# RTS591x register map
Vendor: Realtek Semiconductor Corp.; Series: RTS591x Series; File version: 1.0
CPU: ARMV8MML r0p0, little endian, MPU, FPU, VTOR, 3 interrupt priority bits, 4 SAU regions
Registers are 32-bit, read-write, reset 0x0 unless marked. A register's access mark holds for its fields unless they carry their own. Offsets are from the block's base; [hi:lo] are bit positions; {n}, {i} and the like mark numbered series; 'fields as' and 'values as' point back to an identical list.

## SPIC — SPIC Controller
Base 0x40010200
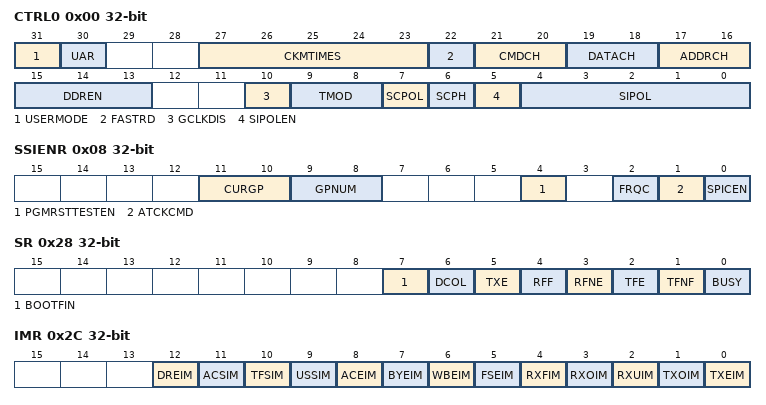
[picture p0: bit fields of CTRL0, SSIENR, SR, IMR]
0x00 CTRL0 — CONTROL #0 REGISTER0
  [31] USERMODE — User Mode Bit
    0=AUTO_MODE (User can't push data to FIFO and set SSIENR to 1); 1=USER_MODE (User can push data to FIFO and set SSIENR to 1)
  [30] UAR — User Mode Bit Auto Reset After Current User Mode Transaction is Over
    0=DISABLE (Disable UAR); 1=ENABLE (Enable UAR)
  [27:23] CKMTIMES — Check Times
  [22] FASTRD — Use Fast Read Command in User Mode
    0=DISABLE; 1=ENABLE (Use FBAUDR to generate spi_sclk)
  [21:20] CMDCH — Channel Number of Command Phase in Transmitting or Receiving Data
    0=SINGLE (Single mode); 1=Dual mode; 2=QUAD (Quad mode); 3=OCTAL (Octal mode)
  [19:18] DATACH — Channel Number of Data in Transmitting or Receiving Data
    values as CMDCH
  [17:16] ADDRCH — Channel Number of Address Phase After Command Phase
    values as CMDCH
  [15:13] DDREN — DDR Mode Enable in CMD_CH/DATA_CH/ADDR_CH
  [10] GCLKDIS — Gate Clock of ICG Cell Disable
    0=ENABLE; 1=DISABLE
  [9:8] TMOD — Transfer Mode
    0=TRANSMIT (Transmit mode); other=RECEIVE (Receive mode)
  [7] SCPOL — Serial Clock Polarity
    0=LOW (INACTIVE state of serial clock is low); 1=HIGH (INACTIVE state of serial clock is high)
  [6] SCPH — Serial Clock Phase
    0=FIRST (Serial clock toggles in middle of first data bit); 1=MIDDLE (Serial clock toggles at start of first data bit)
  [5] SIPOLEN — SIPOL Enable
    0=DISABLE (Disable SIPOL); 1=ENABLE (Enable SIPOL)
  [4:0] SIPOL — SIPOL Mode
0x04 RXNDF — NUMBER OF DATA FRAME
  [23:0] RXNDF — Number of Data Frames
0x08 SSIENR — ENABLE REGISTER
  [11:10] CURGP — Identify Which Group Register Data is Internal Used
  [9:8] GPNUM — Determine Which Group Register User Want to Read or Write
  [4] PGMRSTTESTEN — For PGM RST Test oOnly
    0=INACTIVE (Nothing); 1=ACTIVE (Set to generate a pulse as a warm reset signal and run PGM RST flow)
  [2] FRQC — Set to Enable Frequency Change Function
    0=INACTIVE (Not to activate FRQC); 1=ACTIVE (Activate FRQC)
  [1] ATCKCMD — Set to enable ATCK_CMD implementation
    0=DISABLE (Disable ATCK_CMD); 1=ENABLE (Enable ATCK_CMD)
  [0] SPICEN — Set to Enable SPIC and Start User Mode Transaction
    0=DISABLE (Disable SPIC); 1=ENABLE (Enable SPIC)
0x10 SER — SELECT TARGET FLASH REGISTER
  [0] SLVNUM — Each Bit In The Register Corresponds to One SPI Flash
    0=NOT_SELECTED; 1=SELECTED
0x14 BAUDR — BAUD RATE SELECT REGISTER
  [11:0] SCKDV — Define SPI Clock Divider Value
0x18 TXFTLR — TX FIFO THRESHOLD REGISTER
0x1C RXFTLR — RECEIVE FIFO THRESHOLD LEVEL
0x20 TXFLR — TRANSMIT FIFO LEVEL REGISTER
0x24 RXFLR — RECEIVE FIFO LEVEL REGISTER
0x28 SR — STATUS REGISTER
  [7] BOOTFIN ro — Boot Finish
    0=NOT_FIN (Not finish); 1=FINISH (Boot Finish)
  [6] DCOL — Data Collision
    0=NOT_ERR (Data is not collision); 1=ERROR (Data is collision)
  [5] TXE ro — Transmission error
    0=NOT_ERR (No effect); 1=ERROR (FIFO is empty and starting to transmit data to SPI Flash)
  [4] RFF ro — Receive FIFO full
    0=NOT_FULL (Receive FIFO is not full); 1=FULL (Receive FIFO is full)
  [3] RFNE ro — Receive FIFO is not empty
    0=EMPTY (FIFO is not empty in receiving mode); 1=NOT_EMPTY (FIFO is not empty in receiving mode)
  [2] TFE ro — Transmit FIFO is empty
    0=NOT_EMPTY (Transmit FIFO is not empty); 1=EMPTY (Transmit FIFO is empty)
  [1] TFNF ro — Transmit FIFO is not full
    0=FULL (Transmit FIFO is full); 1=NOT_FULL (Transmit FIFO is not full)
  [0] BUSY ro — SPIC busy flag
    0=IDLE (SPIC is idle); 1=BUSY (SPIC is busy)
0x2C IMR — Interrupt Mask Register
  [12] DREIM — DR timeout error interrupt mask
    1=NO_MASEKED (DR timeout error interrupt is not masked); 0=MASKED (DR timeout error interrupt is masked)
  [11] ACSIM — Auto-check Flash Status raw interrupt mask
    1=NO_MASEKED (Auto-check Flash Status raw interrupt is not masked); 0=MASKED (Auto-check Flash Status raw interrupt is masked)
  [10] TFSIM — Transmit finish interrupt mask
    1=NO_MASEKED (Transmit finish interrupt is not masked); 0=MASKED (Transmit finish interrupt is masked)
  [9] USSIM — User-mode error interrupt mask
    1=NO_MASEKED (User-mode error interrupt is not masked); 0=MASKED (User-mode error interrupt is masked)
  [8] ACEIM — Auto-check timeout error interrupt mask
    1=NO_MASEKED (Auto-check timeout error interrupt is not masked); 0=MASKED (Auto-check timeout error interrupt is masked)
  [7] BYEIM — The Byte-Enable error interrupt mask
    1=NO_MASEKED (The Byte-Enable error interrupt is not masked); 0=MASKED (The Byte-Enable error interrupt is masked)
  [6] WBEIM — Write burst error interrupt mask
    1=NO_MASEKED (Write burst error interrupt is not masked); 0=MASKED (Write burst error interrupt is masked)
  [5] FSEIM — FIFO size error interrupt mask
    1=NO_MASEKED (FIFO size error interrupt is not masked); 0=MASKED (FIFO size error interrupt is masked)
  [4] RXFIM — Receive FIFO full interrupt masked
    1=NO_MASEKED (Receive FIFO full interrupt is not masked); 0=MASKED (Receive FIFO full interrupt is masked)
  [3] RXOIM — Receive FIFO overflow interrupt masked
    1=NO_MASEKED (Receive FIFO overflow interrupt is not masked); 0=MASKED (Receive FIFO overflow interrupt is masked)
  [2] RXUIM — Receive FIFO underflow interrupt masked
    1=NO_MASEKED (Receive FIFO underflow interrupt is not masked); 0=MASKED (Receive FIFO underflow interrupt is masked)
  [1] TXOIM — Transmit FIFO overflow interrupt mask
    1=NO_MASEKED (Transmit FIFO overflow interrupt is not masked); 0=MASKED (Transmit FIFO overflow interrupt is masked)
  [0] TXEIM — Transmit FIFO empty interrupt masked
    1=NO_MASEKED (Transmit FIFO empty interrupt is not masked); 0=MASKED (Transmit FIFO empty interrupt is masked)
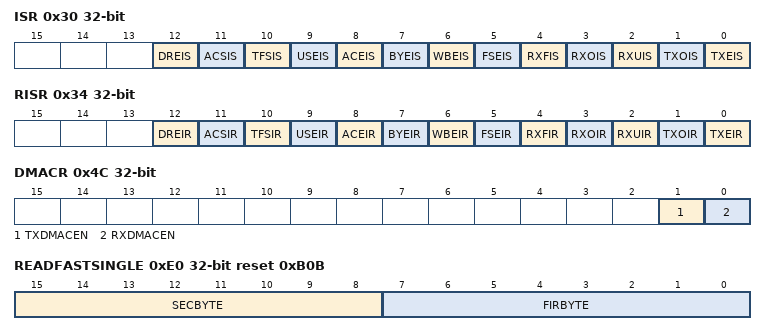
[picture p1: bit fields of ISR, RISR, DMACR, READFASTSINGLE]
0x30 ISR — INTERRUPT STATUS REGISTER
  [12] DREIS ro — DR timeout error interrupt status after masking
    0=INACTIVE (DR timeout error interrupt is not active); 1=ACTIVE (DR timeout error interrupt is active)
  [11] ACSIS ro — Auto-check Flash Status raw interrupt status after masking
    0=INACTIVE (Auto-check Flash Status raw interrupt is not active); 1=ACTIVE (Auto-check Flash Status raw interrupt is active)
  [10] TFSIS ro — Transmit finish status after masking
    0=INACTIVE (Transmit finish is not active); 1=ACTIVE (Transmit finish is active)
  [9] USEIS ro — User mode error status after masking
    0=INACTIVE (User mode error status interrupt is not active); 1=ACTIVE (User mode error status interrupt is active)
  [8] ACEIS ro — Auto-check timeout error interrupt status after masking
    0=INACTIVE (Auto-check timeout error interrupt is not active); 1=ACTIVE (Auto-check timeout error interrupt is active)
  [7] BYEIS ro — The Byte-Enable error interrupt status after masking
    0=INACTIVE (The Byte-Enable error interrupt is not active); 1=ACTIVE (The Byte-Enable error interrupt is active)
  [6] WBEIS ro — Write burst error interrupt status after masking
    0=INACTIVE (Write burst error interrupt is not active); 1=ACTIVE (Write burst error interrupt is active)
  [5] FSEIS ro — FIFO size error interrupt status after masking
    0=INACTIVE (FIFO size error interrupt is not active); 1=ACTIVE (FIFO size error interrupt is active)
  [4] RXFIS ro — Receive FIFO full interrupt status after masking
    0=INACTIVE (Receive FIFO full interrupt is not active); 1=ACTIVE (Receive FIFO full interrupt is active)
  [3] RXOIS ro — Receive FIFO overflow interrupt status after masking
    0=INACTIVE (Receive FIFO overflow interrupt is not active); 1=ACTIVE (Receive FIFO overflow interrupt is active)
  [2] RXUIS ro — Receive FIFO underflow interrupt status after masking
    0=INACTIVE (Receive FIFO underflow interrupt is not active); 1=ACTIVE (Receive FIFO underflow interrupt is active)
  [1] TXOIS ro — Transmit FIFO overflow interrupt status after masking
    0=INACTIVE (Transmit FIFO overflow interrupt is not active); 1=ACTIVE (Transmit FIFO overflow interrupt is active)
  [0] TXEIS ro — Transmit FIFO empty interrupt status after masking
    0=INACTIVE (Transmit FIFO empty interrupt is not active); 1=ACTIVE (Transmit FIFO empty interrupt is active)
0x34 RISR — RAW INTERRUPT STATUS REGISTER
  [12] DREIR ro — Dr Timeout Error Interrupt Status Before Masking
    values as ISR.DREIS
  [11] ACSIR ro — Auto-check Flash Status Raw Interrupt Status Before Masking
    values as ISR.ACSIS
  [10] TFSIR ro — Transmit Finish Status Interrupt Status Before Masking
    0=INACTIVE (Transmit Finish Status interrupt is not active); 1=ACTIVE (Transmit Finish Status interrupt is active)
  [9] USEIR ro — User_mode Error Status Interrupt Status Before Masking
    0=INACTIVE (User_mode error status interrupt is not active); 1=ACTIVE (User_mode error status interrupt is active)
  [8] ACEIR ro — Auto-check Timeout Error Interrupt Status Before Masking
    values as ISR.ACEIS
  [7] BYEIR ro — The Byte-enable Error Interrupt Status Before Masking
    values as ISR.BYEIS
  [6] WBEIR ro — Write Burst Error Interrupt Status Before Masking
    values as ISR.WBEIS
  [5] FSEIR ro — FIFO Size Error Interrupt Status Before Masking
    values as ISR.FSEIS
  [4] RXFIR ro — Receive Fifo Full Interrupt Status Before Masking
    values as ISR.RXFIS
  [3] RXOIR ro — Receive Fifo Overflow Interrupt Status Before Masking
    values as ISR.RXOIS
  [2] RXUIR ro — Receive Fifo Underflow Interrupt Status Before Masking
    values as ISR.RXUIS
  [1] TXOIR ro — Transmit Fifo Overflow Interrupt Status Before Masking
    values as ISR.TXOIS
  [0] TXEIR ro — Transmit Fifo Empty Interrupt Status Before Masking
    values as ISR.TXEIS
0x38 TXOICR — TRANSMIT FIFO OVERFLOW INTERRUPT CLEAR REGISTER
0x3C RXOICR — RECEIVE FIFO OVERFLOW INTERRUPT CLEAR REGISTER
0x40 RXUICR — RECEIVE FIFO UNDERFLOW INTERRUPT CLEAR REGISTER
0x44 MSTICR — MASTER ERROR INTERRUPT CLEAR REGISTER
0x48 ICR — INTERRUPT CLEAR REGISTER
0x4C DMACR — DMA CONTROL REGISTER
  [1] TXDMACEN — Transmit DMA Enable
    0=Disable (Transmit DMA is disable); 1=Enable (Transmit DMA is enable)
  [0] RXDMACEN — Receive DMA Enable
    0=Disable (Receive DMA is disable); 1=Enable (Receive DMA is enable)
0x50 DMATDLR — DMA TRANSMIT DATA LEVEL REGISTER
0x54 DMARDLR — DMA RECEIVE DATA LEVEL REGISTER
0x58 IDR — IDENTIFICATION REGISTER
0x5C VERSION — SPIC VERSION ID REGISTER
{0x60+4i} BYTE[{i}] (i=0..14) (DR view) — DATA REGISTER
{0x60+4i} HALF[{i}] (i=0..14) (DR view) — DATA REGISTER
{0x60+4i} WORD[{i}] (i=0..14) (DR view) — DATA REGISTER
{0xA0+4i} DMDR[{i}] (i=0..14) — Data MASK Register
0xE0 READFASTSINGLE reset 0xB0B — FAST READ DATA COMMAND OF SPI FLASH IN AUTO MODE
  [15:8] SECBYTE — For RD_OCTA_IO_CMD_2nd_BYTE
  [7:0] FIRBYTE — For RD_OCTA_IO_CMD_1st_BYTE
0xE4 READDUALDATA reset 0x3B — DUAL OUTPUT READ COMMAND OF SPI FLASH IN AUTO MODE
  [7:0] CMD — Indicate SPI Flash Command Value Of Dual Data Read Command
0xE8 READDUALADDRDATA reset 0xBB — DUAL I/O READ COMMAND OF SPI FLASH IN AUTO MODE
  [7:0] CMD — Indicate SPI Flash command value of dual address and data read command
0xEC READQUADDATA reset 0x6B — QAUD OUTPUT READ COMMAND OF SPI FLASH IN AUTO MODE
  [7:0] CMD — Indicate SPI Flash Command Value Of Quad Data Read Command
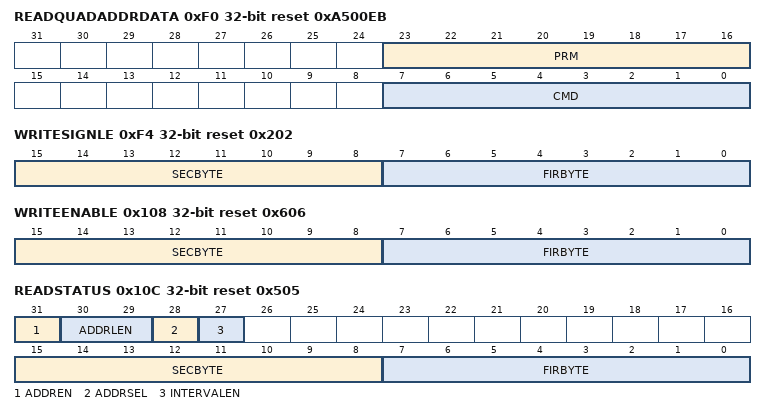
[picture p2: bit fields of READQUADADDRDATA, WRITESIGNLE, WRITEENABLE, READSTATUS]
0xF0 READQUADADDRDATA reset 0xA500EB — QUAD I/O READ COMMAND OF SPI FLASH IN AUTO MODE
  [23:16] PRM — High Performance Read Mode Value
  [7:0] CMD — Indicate SPI Flash Command Value Of Quad Address And Data Read Command
0xF4 WRITESIGNLE reset 0x202 — PAGE PROGRAM COMMAND OF SPI FLASH IN AUTO MODE
  [15:8] SECBYTE — For WR_OCTA_IO_CMD_2nd_BYTE
  [7:0] FIRBYTE — For WR_OCTA_IO_CMD_1st_BYTE
0xF8 WRITEDUALDATA reset 0xA2 — DUAL DATA INPUT PROGRAM COMMAND OF SPI FLASH IN AUTO MODE
  [7:0] CMD — Indicate SPI Flash Command Value Of Dual Data Write Command
0xFC WRITEDUALADDRDATA — DUAL ADDRESS AND DATA OUTPUT READ COMMAND OF SPI FLASH IN AUTO MODE
  [7:0] CMD — Indicate SPI Flash Command Value Of Dual Address And Data Write Command
0x100 WRITEQUADDATA reset 0x32 — QUAD DATA INPUT PROGRAM COMMAND OF SPI FLASH IN AUTO MODE
  [7:0] CMD — Indicate SPI Flash Command Value Of Quad Data Write Command
0x104 WRITEQUADADDRDATA reset 0x38 — QUAD ADDRESS AND DATA OUTPUT WRITE COMMAND OF SPI FLASH IN AUTO MODE
  [7:0] CMD — Indicate SPI Flash Command Value Of Quad Address And Data Write Command
0x108 WRITEENABLE reset 0x606 — WRITE ENABLE COMMAND OF SPI FLASH IN AUTO MODE
  [15:8] SECBYTE — Indicate SPI Flash Command Value Of 2nd Byte Of Write Enable
  [7:0] FIRBYTE — Indicate SPI Flash Command Value Of 1st Byte Of Write Enable
0x10C READSTATUS reset 0x505 — READ STATUS COMMAND OF SPI FLASH IN AUTO MODE
  [31] ADDREN — Indicate SPI Flash Read Status With The Address
    0=WithoutAddr (Without an address); 1=WithAddr (With an address)
  [30:29] ADDRLEN — Indicate SPI Flash Read Status With Address And Address Length
  [28] ADDRSEL — Indicate SPI Flash Read Status With Address And Address Value
    0=32'h0000_0000; 1=32h1 (32'h0000_0001)
  [27] INTERVALEN — Indicate SPI Flash Read Status With 2-byte Status But Checking Only Odd Byte Or Even Byte
    0=Odd (Odd byte); 1=Even byte
  [15:8] SECBYTE — Indicate SPI Flash Command Value Of 2nd Byte Of Read Status
  [7:0] FIRBYTE — Indicate SPI Flash Command Value Of 1st Byte Of Read Status
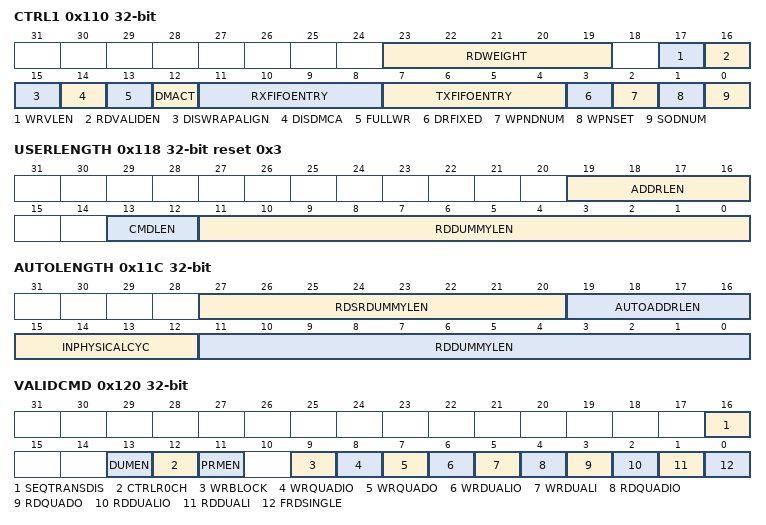
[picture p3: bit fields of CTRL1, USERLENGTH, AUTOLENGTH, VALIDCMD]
0x110 CTRL1 — CONTROL #1 REGISTER
  [23:19] RDWEIGHT — Set To Determine The Read And Write Priority
  [17] WRVLEN — Set To Enable Variable Write Latency
  [16] RDVALIDEN — Set To Enable Variable Read Latency
  [15] DISWRAPALIGN — Set To Disable Wrap_align Function In Auto Mode
  [14] DISDMCA — Set To Disable Spi_dm_oe_n (Let The Device To Drive Dm) When Spic Pushing Cmd And Addr For Both User Mode And Auto Mode
  [13] FULLWR — Set To Enable Full Write In Both User Mode And Auto Mode
  [12] DMACT — DM (Data Mask) is Active High Or Low
  [11:8] RXFIFOENTRY — Indicates The Valid Entry Of RX FIFO
  [7:4] TXFIFOENTRY — Indicates The Valid Entry Of TX FIFO
  [3] DRFIXED — Indicate the AXI FIXED Read Mode on DR
    0=Disable (User mode read DR will be INCR); 1=Enable (User mode read DR will be FIXED)
  [2] WPNDNUM — Indicate The Wpn Input Pin Is Connected To Out[2]or [3]
    0=OUT2 (Connects to spi_sout[2]); 1=OUT3 (Connects to spi_sout[3])
  [1] WPNSET — To Implement Write Protect Function
    0=NotProtected (Write is not wrotected); 1=Protected (Write wrotected)
  [0] SODNUM — Indicate So Input Pin Is Connected To Sout[0] Or [1]
    0=OUT0 (Connects to spi_sout[0]); 1=OUT1 (Connects to spi_sout[1])
0x114 FBAUDR reset 0x1 — FAST BAUD RATE SELECT
  [11:0] FSCKDV — Indicate The Divider Of Fast Read Command When Fast_rd Is Setting In User Mode Or Using Fast Read Command In Auto Mode
0x118 USERLENGTH reset 0x3 — DECIDES BYTE NUMBERS OF COMMAND, ADDRESS AND DATA PHASE TO TRANSMIT
  [19:16] ADDRLEN — Indicate Number Of Bytes In Address Phase In User Mode
  [13:12] CMDLEN — Indicate Number Of Bytes In Command Phase In User Mode
  [11:0] RDDUMMYLEN — Indicate Delay Cycles For Receiving Data In User Mode
0x11C AUTOLENGTH — AUTO ADDRESS LENGTH REGISTER
  [27:20] RDSRDUMMYLEN — Indicate Delay Cycles For Receiving Data After Read Status Register (RDSR) Command
  [19:16] AUTOADDRLEN — Indicate Number Of Bytes Address In Read/write Command In Auto Mode
  [15:12] INPHYSICALCYC — Indicate Number Of Bytes Address In Read/write Command In Auto Mode
  [11:0] RDDUMMYLEN — Indicate Delay Cycles For Receiving Data. It Is Referenced By bus_clk
0x120 VALIDCMD — VALID COMMAND REGISTER
  [16] SEQTRANSDIS — Set 1 to Disable Sequential Read And Sequential Write Function In Auto Mode
    0=Enable sequential read and sequential write function in auto mode; 1=Disable sequential read and sequential write function in auto mode
  [13] DUMEN — Enable To Push One Dummy Byte After Pushing Address To Flash In Auto Read
    0=Disable to push one dummy byte after pushing address to Flash in auto read; 1=Enable to push one dummy byte after pushing address to Flash in auto read
  [12] CTRLR0CH — Use CTRLR0 CMD_CH/DATA_CH/ADDR_CH and DDR_EN Field In Auto Mode
    0=Disable (SPIC will decode according to which VALID_CMD you choose in auto mode); 1=Enable (Use CTRLR0 CMD_CH/DATA_CH/ADDR_CH and DDR_EN field in Auto mode)
  [11] PRMEN — Set to Enable SPIC Performance Read Mode In Auto Mode
    0=Disable SPIC performance read mode; 1=Enable SPIC performance read mode
  [9] WRBLOCK — Write Blocking
    0=Nonblocking (Accept next operation after only check the write data pushing to FIFO); 1=Blocking (Accept next operation after the write data push to FIFO and FIFO is pop data to empty by SPIC.)
  [8] WRQUADIO — Indicate Quad Address/data Write Is A Valid Command To Execute
    0=Invalid (Quad address/data write command is not valid); 1=Valid (Quad address/data write command is valid)
  [7] WRQUADO — Indicate Quad Data Write Is a Valid Command To Execute
    0=Invalid (Quad data write command is not valid); 1=Valid (Quad data write command is valid)
  [6] WRDUALIO — Indicate Dual Address/data Write Is A Valid Command To Execute
    0=Invalid (Dual address/data write command is not valid); 1=Valid (Dual address/data write command is valid)
  [5] WRDUALI — Indicate Dual Data Write Is A Valid Command To Execute
    0=Invalid (Dual data write command is not valid); 1=Valid (Dual data write command is valid)
  [4] RDQUADIO — Indicate Quad Address/data Read Is a Valid Command To Execute
    0=Invalid (Quad address/data read command is not valid); 1=Valid (Quad address/data read command is valid)
  [3] RDQUADO — Indicate Quad Data Read Is a Valid Command To Execute
    0=Invalid (Quad data read command is not valid); 1=Valid (Quad data read command is valid)
  [2] RDDUALIO — Indicate Dual Address/data Read Is a Valid Command To Execute
    0=Invalid (Dual address/data read command is not valid); 1=Valid (Dual address/data read command is valid)
  [1] RDDUALI — Indicate Dual Data Read Is a Valid Command To Execute
    0=Invalid (Dual data read command is not valid); 1=Valid (Dual data read command is valid)
  [0] FRDSINGLE — Indicate Fast Read Command Is a Valid Command To Execute
    0=Invalid (Fast read command is not valid); 1=Valid (Fast read command is valid)
0x124 FLASESIZE — FLASH SIZE REGISTER
  [4:0] SIZE — Indicate The Size Of Flash Size To Select The Target SPI Flash In Auto Mode
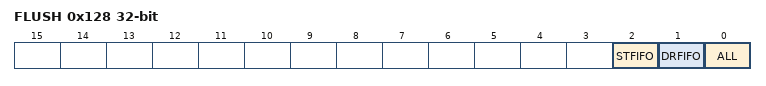
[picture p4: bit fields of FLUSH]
0x128 FLUSH — FLUSH FIFO REGISTER
  [2] STFIFO — Clear All Data in the ST_FIFO
    0=DoNothing; 1=Flush (Clear all data in the ST_FIFO)
  [1] DRFIFO — Clear All Data in the TX_FIFO and RX_FIFO
    0=DoNothing; 1=Flush (Clear all data in the TX_FIFO and RX_FIFO)
  [0] ALL — Clear All Data In All FIFO (Include TX_FIFO, RX_FIFO and ST_FIFO)
    0=DoNothing; 1=Flush (Clear all data in all FIFO (include TX_FIFO, RX_FIFO and ST_FIFO))
0x12C DUMBYTE — CONFIGURE DUMMY BYTE
  [7:0] VAL — Push Dummy Byte Value
0x130 TXNDF — COUNT A NUMBER OF DATA FRAMES OF TX DATA IN USER MODE
0x134 DEVINFO — CONFIGURE THE SPI DEVICE INFORMATION
0x138 TPR0 — TIMING PARAMETERS OF SPI DEVICES
0x13C AUTOLEN2 — THE DELAY CYCLES TO TRANSMIT DATA IN AUTO MODE
0x140 TPR1 — TIMING PARMETERS OF SPI DEVICE
0x1C0 STFLR — NUMBER OF VALID DATA ENTRIES IN STATUS DATA
0x1D0 PAGEREAD — CONFIGURE THE PAGE READ COMMAND IN AUTO MODE
